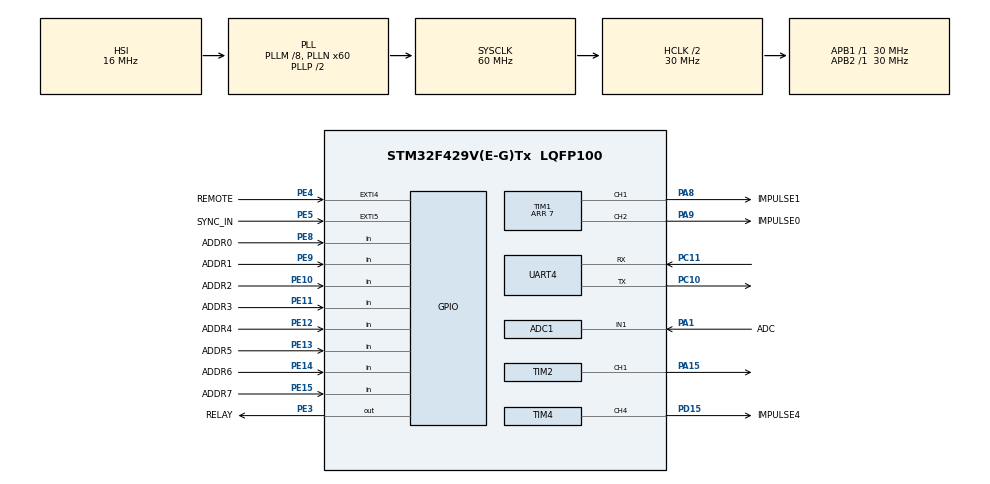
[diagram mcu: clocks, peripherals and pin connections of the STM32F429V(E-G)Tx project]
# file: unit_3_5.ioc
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ADC1.Channel-28\#ChannelRegularConversion=ADC_CHANNEL_1
ADC1.EnableAnalogWatchDog=true
ADC1.HighThreshold=4095
ADC1.ITMode=ENABLE
ADC1.LowThreshold=1
ADC1.NbrOfConversionFlag=1
ADC1.Rank-28\#ChannelRegularConversion=1
ADC1.SamplingTime-28\#ChannelRegularConversion=ADC_SAMPLETIME_3CYCLES
ADC1.WatchdogChannel=ADC_CHANNEL_1
ADC1.master=1
Dma.ADC1.0.Direction=DMA_PERIPH_TO_MEMORY
Dma.ADC1.0.FIFOMode=DMA_FIFOMODE_DISABLE
Dma.ADC1.0.Instance=DMA2_Stream0
Dma.ADC1.0.MemDataAlignment=DMA_MDATAALIGN_HALFWORD
Dma.ADC1.0.MemInc=DMA_MINC_ENABLE
Dma.ADC1.0.Mode=DMA_CIRCULAR
Dma.ADC1.0.PeriphDataAlignment=DMA_PDATAALIGN_HALFWORD
Dma.ADC1.0.PeriphInc=DMA_PINC_DISABLE
Dma.ADC1.0.Priority=DMA_PRIORITY_LOW
Dma.Request0=ADC1
Mcu.Family=STM32F4
Mcu.Name=STM32F429V(E-G)Tx
Mcu.Package=LQFP100
NVIC.ADC_IRQn=true\:0\:0\:false\:false\:true\:true
NVIC.DMA2_Stream0_IRQn=true\:0\:0\:false\:false\:true\:false
NVIC.EXTI4_IRQn=true\:0\:0\:false\:false\:true\:true
NVIC.EXTI9_5_IRQn=true\:0\:0\:false\:false\:true\:true
NVIC.PriorityGroup=NVIC_PRIORITYGROUP_4
NVIC.TIM1_TRG_COM_TIM11_IRQn=true\:0\:0\:false\:false\:true\:true
NVIC.TIM1_UP_TIM10_IRQn=true\:0\:0\:false\:false\:true\:true
NVIC.TIM5_IRQn=true\:0\:0\:false\:false\:true\:true
NVIC.TIM6_DAC_IRQn=true\:0\:0\:false\:false\:true\:true
NVIC.TIM7_IRQn=true\:0\:0\:false\:false\:true\:true
NVIC.TIM8_BRK_TIM12_IRQn=true\:0\:0\:false\:false\:true\:true
NVIC.TIM8_UP_TIM13_IRQn=true\:0\:0\:false\:false\:true\:true
PA1.GPIO_Label=ADC
PA1.Signal=ADCx_IN1
PA15.Signal=S_TIM2_CH1_ETR
PA8.GPIO_Label=IMPULSE1
PA8.GPIO_Speed=GPIO_SPEED_FREQ_VERY_HIGH
PA8.Signal=S_TIM1_CH1
PA9.GPIO_Label=IMPULSE0
PA9.GPIO_Speed=GPIO_SPEED_FREQ_VERY_HIGH
PA9.Signal=S_TIM1_CH2
PC10.Mode=Asynchronous
PC10.Signal=UART4_TX
PC11.Mode=Asynchronous
PC11.Signal=UART4_RX
PD15.GPIO_Label=IMPULSE4
PD15.GPIO_Speed=GPIO_SPEED_FREQ_VERY_HIGH
PD15.Signal=S_TIM4_CH4
PE10.GPIO_Label=ADDR2
PE10.GPIO_PuPd=GPIO_PULLUP
PE10.Signal=GPIO_Input
PE11.GPIO_Label=ADDR3
PE11.GPIO_PuPd=GPIO_PULLUP
PE11.Signal=GPIO_Input
PE12.GPIO_Label=ADDR4
PE12.GPIO_PuPd=GPIO_PULLUP
PE12.Signal=GPIO_Input
PE13.GPIO_Label=ADDR5
PE13.GPIO_PuPd=GPIO_PULLUP
PE13.Signal=GPIO_Input
PE14.GPIO_Label=ADDR6
PE14.GPIO_PuPd=GPIO_PULLUP
PE14.Signal=GPIO_Input
PE15.GPIO_Label=ADDR7
PE15.GPIO_PuPd=GPIO_PULLUP
PE15.Signal=GPIO_Input
PE3.GPIO_Label=RELAY
PE3.GPIO_PuPd=GPIO_NOPULL
PE3.GPIO_Speed=GPIO_SPEED_FREQ_VERY_HIGH
PE3.Signal=GPIO_Output
PE4.GPIO_Label=REMOTE
PE4.GPIO_ModeDefaultEXTI=GPIO_MODE_IT_RISING_FALLING
PE4.GPIO_PuPd=GPIO_PULLDOWN
PE4.Signal=GPXTI4
PE5.GPIO_Label=SYNC_IN
PE5.GPIO_ModeDefaultEXTI=GPIO_MODE_IT_RISING
PE5.GPIO_PuPd=GPIO_NOPULL
PE5.Signal=GPXTI5
PE8.GPIO_Label=ADDR0
PE8.GPIO_PuPd=GPIO_PULLUP
PE8.Signal=GPIO_Input
PE9.GPIO_Label=ADDR1
PE9.GPIO_PuPd=GPIO_PULLUP
PE9.Signal=GPIO_Input
ProjectManager.HeapSize=0x200
ProjectManager.StackSize=0x400
ProjectManager.TargetToolchain=EWARM V8
RCC.48MHZClocksFreq_Value=30000000
RCC.AHBCLKDivider=RCC_SYSCLK_DIV2
RCC.AHBFreq_Value=30000000
RCC.APB1Freq_Value=30000000
RCC.APB1TimFreq_Value=30000000
RCC.APB2Freq_Value=30000000
RCC.APB2TimFreq_Value=30000000
RCC.CortexFreq_Value=30000000
RCC.HCLKFreq_Value=30000000
RCC.HSE_VALUE=25000000
RCC.HSI_VALUE=16000000
RCC.LSE_VALUE=32768
RCC.PLLM=8
RCC.PLLN=60
RCC.SYSCLKFreq_VALUE=60000000
RCC.SYSCLKSource=RCC_SYSCLKSOURCE_PLLCLK
RCC.VCOOutputFreq_Value=120000000
SH.ADCx_IN1.0=ADC1_IN1,IN1
SH.S_TIM1_CH1.0=TIM1_CH1,PWM Generation1 CH1
SH.S_TIM1_CH2.0=TIM1_CH2,PWM Generation2 CH2
SH.S_TIM2_CH1_ETR.0=TIM2_CH1,PWM Generation1 CH1
SH.S_TIM4_CH4.0=TIM4_CH4,PWM Generation4 CH4
TIM1.Channel-PWM\ Generation1\ CH1=TIM_CHANNEL_1
TIM1.Channel-PWM\ Generation2\ CH2=TIM_CHANNEL_2
TIM1.OCFastMode_PWM-PWM\ Generation1\ CH1=TIM_OCFAST_ENABLE
TIM1.OCFastMode_PWM-PWM\ Generation2\ CH2=TIM_OCFAST_ENABLE
TIM1.Period=7
TIM1.Pulse-PWM\ Generation1\ CH1=1
TIM1.Pulse-PWM\ Generation2\ CH2=4
TIM10.Period=(10 * 1000) - 1
TIM10.Prescaler=(30 * 1000) - 1
TIM11.Period=(10 * 1000) - 1
TIM11.Prescaler=(30 * 1000) - 1
TIM12.Period=(1 * 1000) - 1
TIM12.Prescaler=(30 * 1000) - 1
TIM13.Period=(2 * 1000) - 1
TIM13.Prescaler=(30 * 1000) - 1
TIM2.Channel-PWM\ Generation1\ CH1=TIM_CHANNEL_1
TIM2.OCMode_PWM-PWM\ Generation1\ CH1=TIM_OCMODE_PWM2
TIM2.Period=(8 * 94) - 2
TIM2.Pulse-PWM\ Generation1\ CH1=(8 * 94) - (8 * 26)
TIM2.TIM_MasterOutputTrigger=TIM_TRGO_ENABLE
TIM2.TIM_MasterSlaveMode=TIM_MASTERSLAVEMODE_ENABLE
TIM4.Channel-PWM\ Generation4\ CH4=TIM_CHANNEL_4
TIM4.Period=7
TIM4.Pulse-PWM\ Generation4\ CH4=1
TIM5.Period=4
TIM5.Prescaler=1499
TIM5.TIM_MasterOutputTrigger=TIM_TRGO_ENABLE
TIM5.TIM_MasterSlaveMode=TIM_MASTERSLAVEMODE_ENABLE
TIM6.Period=49
TIM6.Prescaler=299
TIM7.Period=(10 * 1000) - 1
TIM7.Prescaler=(30 * 1000) - 1
UART4.VirtualMode=Asynchronous
VP_TIM10_VS_ClockSourceINT.Mode=Enable_Timer
VP_TIM10_VS_OPM.Mode=OPM_bit
VP_TIM11_VS_ClockSourceINT.Mode=Enable_Timer
VP_TIM11_VS_OPM.Mode=OPM_bit
VP_TIM12_VS_ClockSourceINT.Mode=Internal
VP_TIM12_VS_OPM.Mode=OPM_bit
VP_TIM13_VS_ClockSourceINT.Mode=Enable_Timer
VP_TIM13_VS_OPM.Mode=OPM_bit
VP_TIM1_VS_ClockSourceINT.Mode=Internal
VP_TIM1_VS_ClockSourceITR.Mode=TriggerSource_ITR1
VP_TIM1_VS_ControllerModeGated.Mode=Gated Mode
VP_TIM2_VS_ClockSourceINT.Mode=Internal
VP_TIM2_VS_OPM.Mode=OPM_bit
VP_TIM4_VS_ClockSourceINT.Mode=Internal
VP_TIM4_VS_ClockSourceITR.Mode=TriggerSource_ITR1
VP_TIM4_VS_ControllerModeGated.Mode=Gated Mode
VP_TIM5_VS_ClockSourceINT.Mode=Internal
VP_TIM6_VS_ClockSourceINT.Mode=Enable_Timer
VP_TIM7_VS_ClockSourceINT.Mode=Enable_Timer
VP_TIM7_VS_OPM.Mode=OPM_bit
board=custom

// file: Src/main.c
/* USER CODE BEGIN Header */
/**
  ******************************************************************************
  * @file           : main.c
  * @brief          : Main program body
  ******************************************************************************
  ** This notice applies to any and all portions of this file
  * that are not between comment pairs USER CODE BEGIN and
  * USER CODE END. Other portions of this file, whether
  * inserted by the user or by software development tools
  * are owned by their respective copyright owners.
  *
  * COPYRIGHT(c) 2020 STMicroelectronics
  *
  * Redistribution and use in source and binary forms, with or without modification,
  * are permitted provided that the following conditions are met:
  *   1. Redistributions of source code must retain the above copyright notice,
  *      this list of conditions and the following disclaimer.
  *   2. Redistributions in binary form must reproduce the above copyright notice,
  *      this list of conditions and the following disclaimer in the documentation
  *      and/or other materials provided with the distribution.
  *   3. Neither the name of STMicroelectronics nor the names of its contributors
  *      may be used to endorse or promote products derived from this software
  *      without specific prior written permission.
  *
  * THIS SOFTWARE IS PROVIDED BY THE COPYRIGHT HOLDERS AND CONTRIBUTORS "AS IS"
  * AND ANY EXPRESS OR IMPLIED WARRANTIES, INCLUDING, BUT NOT LIMITED TO, THE
  * IMPLIED WARRANTIES OF MERCHANTABILITY AND FITNESS FOR A PARTICULAR PURPOSE ARE
  * DISCLAIMED. IN NO EVENT SHALL THE COPYRIGHT HOLDER OR CONTRIBUTORS BE LIABLE
  * FOR ANY DIRECT, INDIRECT, INCIDENTAL, SPECIAL, EXEMPLARY, OR CONSEQUENTIAL
  * DAMAGES (INCLUDING, BUT NOT LIMITED TO, PROCUREMENT OF SUBSTITUTE GOODS OR
  * SERVICES; LOSS OF USE, DATA, OR PROFITS; OR BUSINESS INTERRUPTION) HOWEVER
  * CAUSED AND ON ANY THEORY OF LIABILITY, WHETHER IN CONTRACT, STRICT LIABILITY,
  * OR TORT (INCLUDING NEGLIGENCE OR OTHERWISE) ARISING IN ANY WAY OUT OF THE USE
  * OF THIS SOFTWARE, EVEN IF ADVISED OF THE POSSIBILITY OF SUCH DAMAGE.
  *
  ******************************************************************************
  */
/* USER CODE END Header */

#include "main.h"
#include "adc.h"
#include "dma.h"
#include "tim.h"
#include "usart.h"
#include "gpio.h"

/* USER CODE BEGIN Includes */
#include "loop.h"
/* USER CODE END Includes */

void SystemClock_Config(void);

int main(void)
{

  /* MCU Configuration--------------------------------------------------------*/

  /* Reset of all peripherals, Initializes the Flash interface and the Systick. */
  HAL_Init();

  /* Configure the system clock */
  SystemClock_Config();

  /* Initialize all configured peripherals */
  MX_GPIO_Init();
  MX_DMA_Init();
  MX_TIM1_Init();
  MX_TIM4_Init();
  MX_TIM2_Init();
  MX_TIM5_Init();
  MX_ADC1_Init();
  MX_TIM6_Init();
  MX_TIM10_Init();
  MX_TIM11_Init();
  MX_UART4_Init();
  MX_TIM12_Init();
  MX_TIM7_Init();
  MX_TIM13_Init();
  /* USER CODE BEGIN 2 */
  loop();
  /* USER CODE END 2 */

  /* Infinite loop */
  while (1)
  {

  }
}

void SystemClock_Config(void)
{
  RCC_OscInitTypeDef RCC_OscInitStruct = {0};
  RCC_ClkInitTypeDef RCC_ClkInitStruct = {0};

  /**Configure the main internal regulator output voltage
  */
  __HAL_RCC_PWR_CLK_ENABLE();
  __HAL_PWR_VOLTAGESCALING_CONFIG(PWR_REGULATOR_VOLTAGE_SCALE3);
  /**Initializes the CPU, AHB and APB busses clocks
  */
  RCC_OscInitStruct.OscillatorType = RCC_OSCILLATORTYPE_HSI;
  RCC_OscInitStruct.HSIState = RCC_HSI_ON;
  RCC_OscInitStruct.HSICalibrationValue = RCC_HSICALIBRATION_DEFAULT;
  RCC_OscInitStruct.PLL.PLLState = RCC_PLL_ON;
  RCC_OscInitStruct.PLL.PLLSource = RCC_PLLSOURCE_HSI;
  RCC_OscInitStruct.PLL.PLLM = 8;
  RCC_OscInitStruct.PLL.PLLN = 60;
  RCC_OscInitStruct.PLL.PLLP = RCC_PLLP_DIV2;
  RCC_OscInitStruct.PLL.PLLQ = 4;
  if (HAL_RCC_OscConfig(&RCC_OscInitStruct) != HAL_OK)
  {
    Error_Handler();
  }
  /**Initializes the CPU, AHB and APB busses clocks
  */
  RCC_ClkInitStruct.ClockType = RCC_CLOCKTYPE_HCLK|RCC_CLOCKTYPE_SYSCLK
                              |RCC_CLOCKTYPE_PCLK1|RCC_CLOCKTYPE_PCLK2;
  RCC_ClkInitStruct.SYSCLKSource = RCC_SYSCLKSOURCE_PLLCLK;
  RCC_ClkInitStruct.AHBCLKDivider = RCC_SYSCLK_DIV2;
  RCC_ClkInitStruct.APB1CLKDivider = RCC_HCLK_DIV1;
  RCC_ClkInitStruct.APB2CLKDivider = RCC_HCLK_DIV1;

  if (HAL_RCC_ClockConfig(&RCC_ClkInitStruct, FLASH_LATENCY_0) != HAL_OK)
  {
    Error_Handler();
  }
}

void Error_Handler(void)
{
}

/************************ (C) COPYRIGHT STMicroelectronics *****END OF FILE****/
